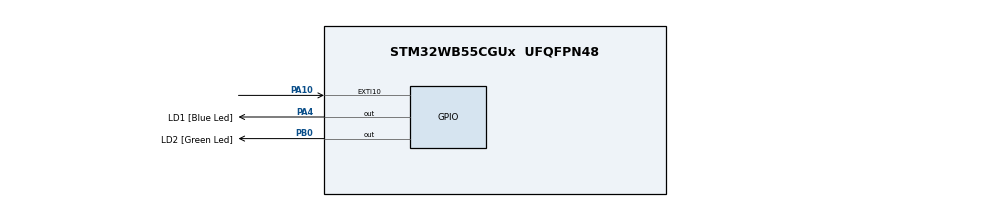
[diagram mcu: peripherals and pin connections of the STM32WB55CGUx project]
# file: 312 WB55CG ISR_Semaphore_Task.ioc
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FREERTOS.Tasks01=defaultTask,24,128,StartDefaultTask,Default,NULL,Dynamic,NULL,NULL;GreenTask,24,128,StartTask02,Default,NULL,Dynamic,NULL,NULL;BlueTask,16,128,StartTask03,Default,NULL,Dynamic,NULL,NULL
Mcu.Family=STM32WB
Mcu.Name=STM32WB55CGUx
Mcu.Package=UFQFPN48
NVIC.EXTI15_10_IRQn=true\:5\:0\:false\:false\:true\:true\:true\:true\:true
NVIC.PriorityGroup=NVIC_PRIORITYGROUP_4
NVIC.TIM1_UP_TIM16_IRQn=true\:15\:0\:false\:false\:true\:false\:false\:true\:true
NVIC.TimeBase=TIM1_UP_TIM16_IRQn
NVIC.TimeBaseIP=TIM16
OSC_IN.GPIO_Label=RCC_OSC_IN
OSC_IN.Mode=HSE-External-Oscillator
OSC_IN.Signal=RCC_OSC_IN
OSC_OUT.GPIO_Label=RCC_OSC_OUT
OSC_OUT.Mode=HSE-External-Oscillator
OSC_OUT.Signal=RCC_OSC_OUT
PA10.Signal=GPXTI10
PA13.Mode=Serial_Wire
PA13.Signal=SYS_JTMS-SWDIO
PA14.Mode=Serial_Wire
PA14.Signal=SYS_JTCK-SWCLK
PA4.GPIO_Label=LD1 [Blue Led]
PA4.Signal=GPIO_Output
PB0.GPIO_Label=LD2 [Green Led]
PB0.Signal=GPIO_Output
PC14-OSC32_IN.GPIO_Label=RCC_OSC32_IN
PC14-OSC32_IN.Mode=LSE-External-Oscillator
PC14-OSC32_IN.Signal=RCC_OSC32_IN
PC15-OSC32_OUT.GPIO_Label=RCC_OSC32_OUT
PC15-OSC32_OUT.Mode=LSE-External-Oscillator
PC15-OSC32_OUT.Signal=RCC_OSC32_OUT
ProjectManager.HeapSize=0x200
ProjectManager.StackSize=0x400
ProjectManager.TargetToolchain=STM32CubeIDE
RCC.ADCFreq_Value=48000000
RCC.AHBFreq_Value=4000000
RCC.APB1Freq_Value=4000000
RCC.APB1TimFreq_Value=4000000
RCC.APB2Freq_Value=4000000
RCC.APB2TimFreq_Value=4000000
RCC.APB3Freq_Value=16000000
RCC.CortexFreq_Value=4000000
RCC.HCLKFreq_Value=4000000
RCC.HSE_VALUE=32000000
RCC.HSI48_VALUE=48000000
RCC.HSI_VALUE=16000000
RCC.PLLN=32
RCC.PLLSAI1N=24
RCC.SMPSDivider=1
RCC.SYSCLKFreq_VALUE=4000000
RCC.USBFreq_Value=48000000
RCC.VCOOutputFreq_Value=128000000
VP_FREERTOS_VS_CMSIS_V2.Mode=CMSIS_V2
VP_MEMORYMAP_VS_MEMORYMAP.Mode=CurAppReg
VP_SYS_VS_tim16.Mode=TIM16
board=P-NUCLEO-WB55-USBDONGLE

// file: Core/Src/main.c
/* USER CODE BEGIN Header */
/**
  ******************************************************************************
  * @file           : main.c
  * @brief          : Main program body
  ******************************************************************************
  * @attention
  *
  * Copyright (c) 2026 STMicroelectronics.
  * All rights reserved.
  *
  * This software is licensed under terms that can be found in the LICENSE file
  * in the root directory of this software component.
  * If no LICENSE file comes with this software, it is provided AS-IS.
  *
  ******************************************************************************
  */

/*
What We Built
Hardware

STM32WB55CG Dongle
Green LED (LD1)
Blue LED (LD2)
Push Button on PA10

RTOS Components

Task (BlueTask)
Binary Semaphore
External Interrupt (EXTI)

Execution Flow

Button Press
     ↓
PA10 Interrupt Occurs
     ↓
HAL_GPIO_EXTI_Callback()
     ↓
xSemaphoreGiveFromISR()
     ↓
Semaphore becomes available
     ↓
BlueTask wakes up
     ↓
xSemaphoreTake() succeeds
     ↓
Blue LED toggles

*/

/* USER CODE END Header */
#include "main.h"
#include "cmsis_os.h"

/* USER CODE BEGIN Includes */
#include "FreeRTOS.h"
#include "semphr.h"
/* USER CODE END Includes */

/* Definitions for defaultTask */
osThreadId_t defaultTaskHandle;
const osThreadAttr_t defaultTask_attributes = {
  .name = "defaultTask",
  .priority = (osPriority_t) osPriorityNormal,
  .stack_size = 128 * 4
};
/* Definitions for GreenTask */
osThreadId_t GreenTaskHandle;
const osThreadAttr_t GreenTask_attributes = {
  .name = "GreenTask",
  .priority = (osPriority_t) osPriorityNormal,
  .stack_size = 128 * 4
};
/* Definitions for BlueTask */
osThreadId_t BlueTaskHandle;
const osThreadAttr_t BlueTask_attributes = {
  .name = "BlueTask",
  .priority = (osPriority_t) osPriorityBelowNormal,
  .stack_size = 128 * 4
};
/* USER CODE BEGIN PV */
SemaphoreHandle_t mySemaphore;
/* USER CODE END PV */

void SystemClock_Config(void);
void PeriphCommonClock_Config(void);
static void MX_GPIO_Init(void);
void StartDefaultTask(void *argument);
void StartTask02(void *argument);
void StartTask03(void *argument);

int main(void)
{

  /* MCU Configuration--------------------------------------------------------*/

  /* Reset of all peripherals, Initializes the Flash interface and the Systick. */
  HAL_Init();

  /* Configure the system clock */
  SystemClock_Config();

  /* Configure the peripherals common clocks */
  PeriphCommonClock_Config();

  /* Initialize all configured peripherals */
  MX_GPIO_Init();

  /* Init scheduler */
  osKernelInitialize();

  /* USER CODE BEGIN RTOS_SEMAPHORES */
  /* add semaphores, ... */
  mySemaphore = xSemaphoreCreateBinary();
  /* USER CODE END RTOS_SEMAPHORES */

  /* Create the thread(s) */
  /* creation of defaultTask */
  defaultTaskHandle = osThreadNew(StartDefaultTask, NULL, &defaultTask_attributes);

  /* creation of GreenTask */
  GreenTaskHandle = osThreadNew(StartTask02, NULL, &GreenTask_attributes);

  /* creation of BlueTask */
  BlueTaskHandle = osThreadNew(StartTask03, NULL, &BlueTask_attributes);

  /* Start scheduler */
  osKernelStart();

  /* We should never get here as control is now taken by the scheduler */

  /* Infinite loop */
  while (1)
  {

  }
}

void SystemClock_Config(void)
{
  RCC_OscInitTypeDef RCC_OscInitStruct = {0};
  RCC_ClkInitTypeDef RCC_ClkInitStruct = {0};

  /** Configure the main internal regulator output voltage
  */
  __HAL_PWR_VOLTAGESCALING_CONFIG(PWR_REGULATOR_VOLTAGE_SCALE1);

  /** Initializes the RCC Oscillators according to the specified parameters
  * in the RCC_OscInitTypeDef structure.
  */
  RCC_OscInitStruct.OscillatorType = RCC_OSCILLATORTYPE_HSI|RCC_OSCILLATORTYPE_HSE
                              |RCC_OSCILLATORTYPE_MSI;
  RCC_OscInitStruct.HSEState = RCC_HSE_ON;
  RCC_OscInitStruct.HSIState = RCC_HSI_ON;
  RCC_OscInitStruct.MSIState = RCC_MSI_ON;
  RCC_OscInitStruct.HSICalibrationValue = RCC_HSICALIBRATION_DEFAULT;
  RCC_OscInitStruct.MSICalibrationValue = RCC_MSICALIBRATION_DEFAULT;
  RCC_OscInitStruct.MSIClockRange = RCC_MSIRANGE_6;
  RCC_OscInitStruct.PLL.PLLState = RCC_PLL_NONE;
  if (HAL_RCC_OscConfig(&RCC_OscInitStruct) != HAL_OK)
  {
    Error_Handler();
  }

  /** Configure the SYSCLKSource, HCLK, PCLK1 and PCLK2 clocks dividers
  */
  RCC_ClkInitStruct.ClockType = RCC_CLOCKTYPE_HCLK4|RCC_CLOCKTYPE_HCLK2
                              |RCC_CLOCKTYPE_HCLK|RCC_CLOCKTYPE_SYSCLK
                              |RCC_CLOCKTYPE_PCLK1|RCC_CLOCKTYPE_PCLK2;
  RCC_ClkInitStruct.SYSCLKSource = RCC_SYSCLKSOURCE_MSI;
  RCC_ClkInitStruct.AHBCLKDivider = RCC_SYSCLK_DIV1;
  RCC_ClkInitStruct.APB1CLKDivider = RCC_HCLK_DIV1;
  RCC_ClkInitStruct.APB2CLKDivider = RCC_HCLK_DIV1;
  RCC_ClkInitStruct.AHBCLK2Divider = RCC_SYSCLK_DIV1;
  RCC_ClkInitStruct.AHBCLK4Divider = RCC_SYSCLK_DIV1;

  if (HAL_RCC_ClockConfig(&RCC_ClkInitStruct, FLASH_LATENCY_0) != HAL_OK)
  {
    Error_Handler();
  }
}

void PeriphCommonClock_Config(void)
{
  RCC_PeriphCLKInitTypeDef PeriphClkInitStruct = {0};

  /** Initializes the peripherals clock
  */
  PeriphClkInitStruct.PeriphClockSelection = RCC_PERIPHCLK_SMPS;
  PeriphClkInitStruct.SmpsClockSelection = RCC_SMPSCLKSOURCE_HSI;
  PeriphClkInitStruct.SmpsDivSelection = RCC_SMPSCLKDIV_RANGE0;

  if (HAL_RCCEx_PeriphCLKConfig(&PeriphClkInitStruct) != HAL_OK)
  {
    Error_Handler();
  }
}

static void MX_GPIO_Init(void)
{
  GPIO_InitTypeDef GPIO_InitStruct = {0};

  /* GPIO Ports Clock Enable */
  __HAL_RCC_GPIOC_CLK_ENABLE();
  __HAL_RCC_GPIOA_CLK_ENABLE();
  __HAL_RCC_GPIOB_CLK_ENABLE();

  /*Configure GPIO pin Output Level */
  HAL_GPIO_WritePin(LD1_GPIO_Port, LD1_Pin, GPIO_PIN_RESET);

  /*Configure GPIO pin Output Level */
  HAL_GPIO_WritePin(LD2_GPIO_Port, LD2_Pin, GPIO_PIN_RESET);

  /*Configure GPIO pin : LD1_Pin */
  GPIO_InitStruct.Pin = LD1_Pin;
  GPIO_InitStruct.Mode = GPIO_MODE_OUTPUT_PP;
  GPIO_InitStruct.Pull = GPIO_NOPULL;
  GPIO_InitStruct.Speed = GPIO_SPEED_FREQ_LOW;
  HAL_GPIO_Init(LD1_GPIO_Port, &GPIO_InitStruct);

  /*Configure GPIO pin : LD2_Pin */
  GPIO_InitStruct.Pin = LD2_Pin;
  GPIO_InitStruct.Mode = GPIO_MODE_OUTPUT_PP;
  GPIO_InitStruct.Pull = GPIO_NOPULL;
  GPIO_InitStruct.Speed = GPIO_SPEED_FREQ_LOW;
  HAL_GPIO_Init(LD2_GPIO_Port, &GPIO_InitStruct);

  /*Configure GPIO pin : PA10 */
  GPIO_InitStruct.Pin = GPIO_PIN_10;
  GPIO_InitStruct.Mode = GPIO_MODE_IT_FALLING;
  GPIO_InitStruct.Pull = GPIO_PULLUP;
  HAL_GPIO_Init(GPIOA, &GPIO_InitStruct);

  /* EXTI interrupt init*/
  HAL_NVIC_SetPriority(EXTI15_10_IRQn, 5, 0);
  HAL_NVIC_EnableIRQ(EXTI15_10_IRQn);

}

/* USER CODE BEGIN 4 */
void HAL_GPIO_EXTI_Callback(uint16_t GPIO_Pin)
{
  BaseType_t xHigherPriorityTaskWoken = pdFALSE;

  if(GPIO_Pin == GPIO_PIN_10)
  {
    HAL_GPIO_TogglePin(LD1_GPIO_Port, LD1_Pin);

    xSemaphoreGiveFromISR(mySemaphore, &xHigherPriorityTaskWoken);

    portYIELD_FROM_ISR(xHigherPriorityTaskWoken);
  }
}
/* USER CODE END 4 */

void StartDefaultTask(void *argument)
{
  for(;;)
  {
    osDelay(1);
  }
}

void StartTask02(void *argument)
{
  for(;;)
  {
    osDelay(1);
  }
}

void StartTask03(void *argument)
{
  /* USER CODE BEGIN StartTask03 */
  /* Infinite loop */
  for(;;)
  {
    xSemaphoreTake(mySemaphore, portMAX_DELAY);

    HAL_GPIO_TogglePin(LD2_GPIO_Port, LD2_Pin);
  }
  /* USER CODE END StartTask03 */
}

void HAL_TIM_PeriodElapsedCallback(TIM_HandleTypeDef *htim)
{
  if (htim->Instance == TIM16)
  {
    HAL_IncTick();
  }
}

void Error_Handler(void)
{
  __disable_irq();
  while (1)
  {
  }
}

/*
Semaphore is only for notification.

Example:

Button pressed
ADC completed
UART completed
DMA completed

No data needed.

Only notification.

A semaphore is used for task synchronization.
In my STM32WB55 FreeRTOS project,
an external interrupt from a button released a binary semaphore using xSemaphoreGiveFromISR().
A task blocked on xSemaphoreTake() woke up and toggled an LED.
This avoids polling and allows efficient event-driven execution.

*/
